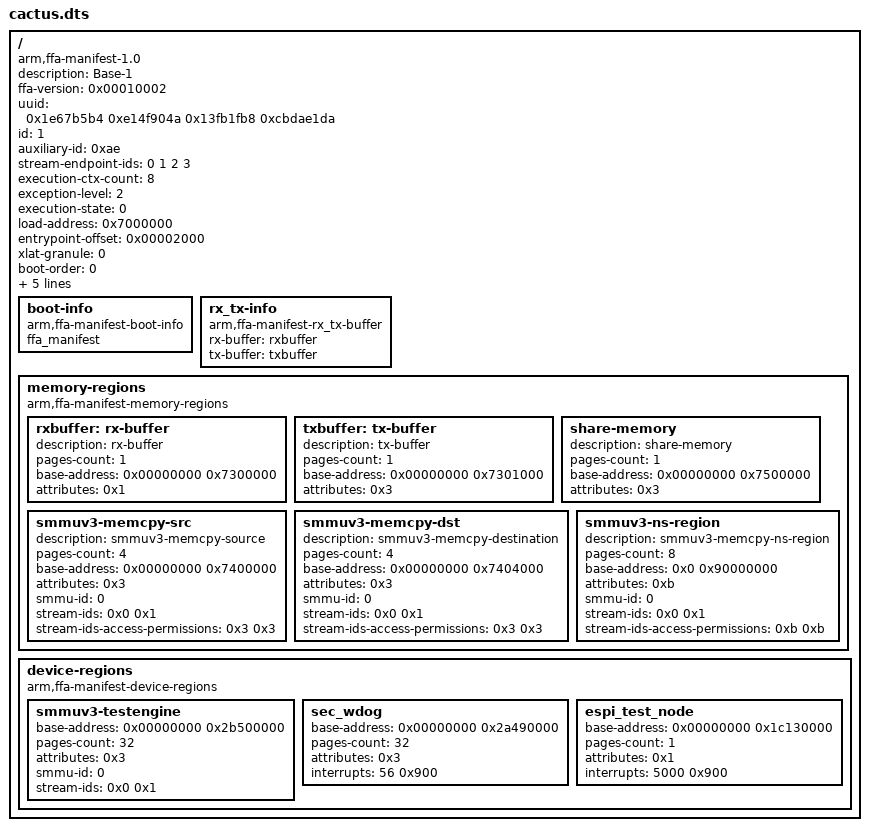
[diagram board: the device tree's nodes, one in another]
/*
 * Copyright (c) 2019-2025, Arm Limited. All rights reserved.
 *
 * SPDX-License-Identifier: BSD-3-Clause
 *
 * This file is a Partition Manifest (PM) for a minimal Secure Partition (SP)
 * that has additional optional properties defined.
 *
 */

/dts-v1/;

/ {
	compatible = "arm,ffa-manifest-1.0";

	/* Properties */
	description = "Base-1";
	ffa-version = <0x00010002>; /* 31:16 - Major, 15:0 - Minor */
	uuid = <0x1e67b5b4 0xe14f904a 0x13fb1fb8 0xcbdae1da>;
	id = <1>;
	auxiliary-id = <0xae>;
	stream-endpoint-ids = <0 1 2 3>;
	execution-ctx-count = <8>;
	exception-level = <2>; /* S-EL1 */
	execution-state = <0>; /* AARCH64 */
	load-address = <0x7000000>;
	entrypoint-offset = <0x00002000>;
	xlat-granule = <0>; /* 4KiB */
	boot-order = <0>;
	messaging-method = <7>; /* Indirect Messaging and direct messaging. */
	ns-interrupts-action = <1>; /* Managed exit is supported */
	notification-support; /* Support receipt of notifications. */
	power-management-messages = <1>; /* Support CPU_OFF power management message. */

	/* Boot protocol */
	gp-register-num = <0>;

	/* Boot Info */
	boot-info {
		compatible = "arm,ffa-manifest-boot-info";
		ffa_manifest;
	};

	rx_tx-info {
		compatible = "arm,ffa-manifest-rx_tx-buffer";
		rx-buffer = <&rxbuffer>;
		tx-buffer = <&txbuffer>;
	};

	memory-regions {
		compatible = "arm,ffa-manifest-memory-regions";

		rxbuffer: rx-buffer {
			description = "rx-buffer";
			pages-count = <1>;
			base-address = <0x00000000 0x7300000>;
			attributes = <0x1>; /* read-only */
		};

		txbuffer: tx-buffer {
			description = "tx-buffer";
			pages-count = <1>;
			base-address = <0x00000000 0x7301000>;
			attributes = <0x3>; /* read-write */
		};

		/* Memory to be shared in memory sharing tests. */
		share-memory {
			description = "share-memory";
			pages-count = <1>;
			base-address =<0x00000000 0x7500000>;
			attributes = <0x3>; /* read-write */
		};

		/*
		 * Scratch memory used for the purpose of testing SMMUv3 driver
		 * through Cactus SP
		 */
		smmuv3-memcpy-src {
			description = "smmuv3-memcpy-source";
			pages-count = <4>;
			base-address = <0x00000000 0x7400000>;
			attributes = <0x3>; /* read-write */
			smmu-id = <0>;
			stream-ids = <0x0 0x1>;
			stream-ids-access-permissions = <0x3 0x3>;
		};

		smmuv3-memcpy-dst {
			description = "smmuv3-memcpy-destination";
			pages-count = <4>;
			base-address = <0x00000000 0x7404000>;
			attributes = <0x3>; /* read-write */
			smmu-id = <0>;
			stream-ids = <0x0 0x1>;
			stream-ids-access-permissions = <0x3 0x3>;
		};

		smmuv3-ns-region {
			description = "smmuv3-memcpy-ns-region";
			pages-count = <8>;
			base-address = <0x0 0x90000000>;
			attributes = <0xb>; /* ns-read-write */
			smmu-id = <0>;
			stream-ids = <0x0 0x1>;
			stream-ids-access-permissions = <0xb 0xb>;
		};
	};

	device-regions {
		compatible = "arm,ffa-manifest-device-regions";

		smmuv3-testengine {
			/*
			 * SMMUv3TestEngine is a DMA IP modeled in the
			 * Base-RevC FVP Model.
			 * User Frame: 0x2b500000
			 * Privileged Frame: 0x25100000
			 */
			base-address = <0x00000000 0x2b500000>;
			pages-count = <32>; /* Two 64KB pages */
			attributes = <0x3>; /* read-write */
			smmu-id = <0>;
			stream-ids = <0x0 0x1>;
		};

		sec_wdog {
			/* SP805 Trusted Watchdog Module */
			base-address = <0x00000000 0x2a490000>;
			pages-count = <32>; /* Two 64KB pages */
			attributes = <0x3>; /* read-write */
			interrupts = <56 0x900>;
		};

		espi_test_node {
			/*
			 * A dummy device region node representing a fake
			 * peripheral. Explicitly used to specify properties of
			 * interrupt 5000, in the extended SPI range, used for
			 * testing purposes. All the properties below except
			 * `interrupts` are irrelevant.
			 */
			base-address = <0x00000000 0x1c130000>;
			pages-count = <1>; /* One 4KB page */
			attributes = <0x1>; /* read-only */
			interrupts = <5000 0x900>;
		};
	};
};
